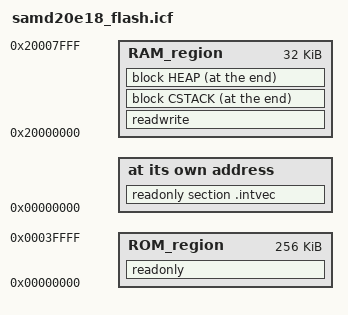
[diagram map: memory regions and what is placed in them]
/**
 * \file
 *
 * \brief Linker script for running in internal FLASH on the SAMD20E18
 *
 * Copyright (c) 2015 Atmel Corporation. All rights reserved.
 *
 * \asf_license_start
 *
 * \page License
 *
 * Redistribution and use in source and binary forms, with or without
 * modification, are permitted provided that the following conditions are met:
 *
 * 1. Redistributions of source code must retain the above copyright notice,
 *    this list of conditions and the following disclaimer.
 *
 * 2. Redistributions in binary form must reproduce the above copyright notice,
 *    this list of conditions and the following disclaimer in the documentation
 *    and/or other materials provided with the distribution.
 *
 * 3. The name of Atmel may not be used to endorse or promote products derived
 *    from this software without specific prior written permission.
 *
 * 4. This software may only be redistributed and used in connection with an
 *    Atmel microcontroller product.
 *
 * THIS SOFTWARE IS PROVIDED BY ATMEL "AS IS" AND ANY EXPRESS OR IMPLIED
 * WARRANTIES, INCLUDING, BUT NOT LIMITED TO, THE IMPLIED WARRANTIES OF
 * MERCHANTABILITY, FITNESS FOR A PARTICULAR PURPOSE AND NON-INFRINGEMENT ARE
 * EXPRESSLY AND SPECIFICALLY DISCLAIMED. IN NO EVENT SHALL ATMEL BE LIABLE FOR
 * ANY DIRECT, INDIRECT, INCIDENTAL, SPECIAL, EXEMPLARY, OR CONSEQUENTIAL
 * DAMAGES (INCLUDING, BUT NOT LIMITED TO, PROCUREMENT OF SUBSTITUTE GOODS
 * OR SERVICES; LOSS OF USE, DATA, OR PROFITS; OR BUSINESS INTERRUPTION)
 * HOWEVER CAUSED AND ON ANY THEORY OF LIABILITY, WHETHER IN CONTRACT,
 * STRICT LIABILITY, OR TORT (INCLUDING NEGLIGENCE OR OTHERWISE) ARISING IN
 * ANY WAY OUT OF THE USE OF THIS SOFTWARE, EVEN IF ADVISED OF THE
 * POSSIBILITY OF SUCH DAMAGE.
 *
 * \asf_license_stop
 *
 */
 /**
 * Support and FAQ: visit <a href="http://www.atmel.com/design-support/">Atmel Support</a>
 */

/*###ICF### Section handled by ICF editor, don't touch! ****/
/*-Editor annotation file-*/
/* IcfEditorFile="$TOOLKIT_DIR$\config\ide\IcfEditor\cortex_v1_0.xml" */
/*-Specials-*/
define symbol __ICFEDIT_intvec_start__        = 0x00000000;
/*-Memory Regions-*/
define symbol __ICFEDIT_region_RAM_start__    = 0x20000000;
define symbol __ICFEDIT_region_RAM_end__      = 0x20007FFF;
define symbol __ICFEDIT_region_ROM_start__    = 0x00000000;
define symbol __ICFEDIT_region_ROM_end__      = 0x0003FFFF;
/*-Sizes-*/
if (!isdefinedsymbol(__ICFEDIT_size_cstack__)) {
  define symbol __ICFEDIT_size_cstack__    = 0x2000;
}
if (!isdefinedsymbol(__ICFEDIT_size_heap__)) {
  define symbol __ICFEDIT_size_heap__      = 0x0;
}
/**** End of ICF editor section. ###ICF###*/

define memory mem with size = 4G;
define region RAM_region    = mem:[from __ICFEDIT_region_RAM_start__ to __ICFEDIT_region_RAM_end__];
define region ROM_region    = mem:[from __ICFEDIT_region_ROM_start__ to __ICFEDIT_region_ROM_end__];

define block CSTACK with alignment = 8, size = __ICFEDIT_size_cstack__ { };
define block HEAP   with alignment = 8, size = __ICFEDIT_size_heap__   { };

initialize by copy { readwrite };
do not initialize  { section .noinit };

place at address mem:__ICFEDIT_intvec_start__ { readonly section .intvec };
place in ROM_region                           { readonly };
place in RAM_region                           { readwrite };
place at end of RAM_region                    { block CSTACK, block HEAP };
